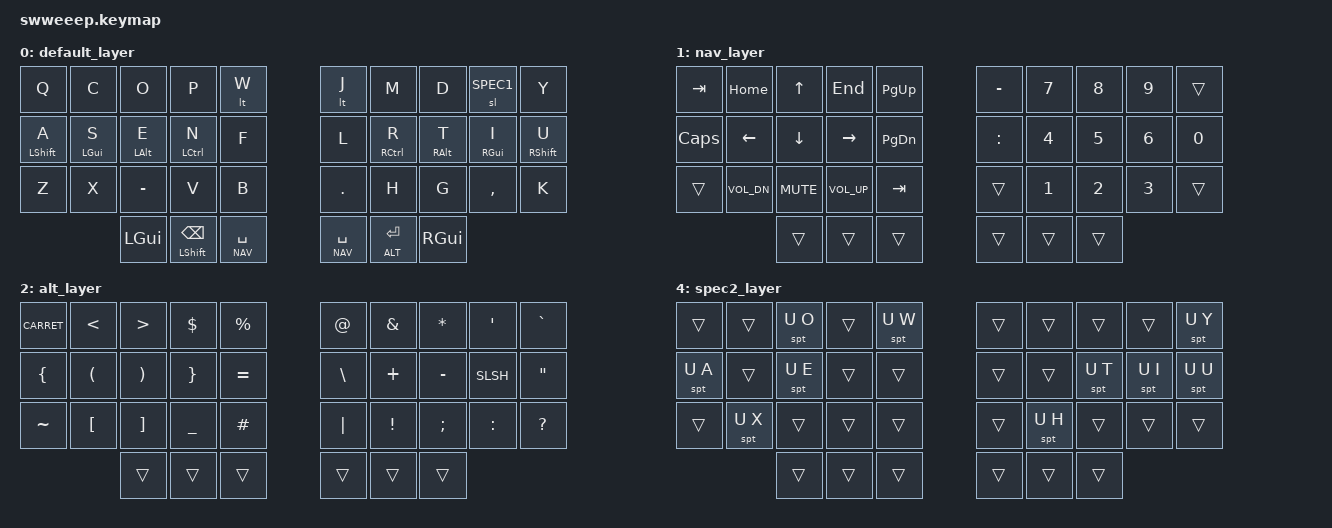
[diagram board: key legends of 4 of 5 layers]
#include <behaviors.dtsi>
#include <dt-bindings/zmk/keys.h>
#include <dt-bindings/zmk/bt.h>
#include <dt-bindings/zmk/ext_power.h>
#include <dt-bindings/zmk/outputs.h>

#define ERGOL   0
#define NAV     1
#define ALT     2
#define SPEC1   3
#define SPEC2   4

&caps_word {
    continue-list = <UNDERSCORE MINUS>;
};

/ {
    combos {
        compatible = "zmk,combos";
        combo_undo {
            timeout-ms = <50>;
            key-positions = <20 21>;
            bindings = <&kp LC(Z)>;
        };
    };
};

/ {
    macros {
	spt: spt {
            compatible = "zmk,behavior-macro";
            #binding-cells = <2>;
            bindings
                = <&macro_press &kp LALT>
                , <&macro_param_1to1>
                , <&macro_release &kp MACRO_PLACEHOLDER>
                , <&macro_release &kp LALT>
		, <&macro_tap &kp LALT>
                , <&macro_param_2to1>
                , <&macro_release &kp MACRO_PLACEHOLDER>
                ;
	};
    };

    behaviors {
        hm: homerow_mods {
            compatible = "zmk,behavior-hold-tap";
            #binding-cells = <2>;
            tapping-term-ms = <200>;
            flavor = "tap-preferred";
            bindings = <&kp>, <&kp>;
        };
        hs: homerow_shift {
            compatible = "zmk,behavior-hold-tap";
            #binding-cells = <2>;
            tapping-term-ms = <175>;
            flavor = "balanced";
            bindings = <&kp>, <&kp>;
        };
    };

    keymap {
        compatible = "zmk,keymap";

        default_layer {
            bindings = <
    &kp Q        &kp C        &kp O       &kp P         &lt W                                       &lt J       &kp M      &kp D      &sl SPEC1  &kp Y
    &hs LSHIFT A &hm LGUI S   &hm LALT E  &hm LCTL N    &kp F                                       &kp L       &hm RCTL R &hm RALT T &hm RGUI I &hs RSHIFT U
    &kp Z        &kp X        &kp -       &kp V         &kp B                                       &kp DOT     &kp H      &kp G      &kp COMMA  &kp K
                                          &kp LGUI      &hs LSHIFT BSPC &lt NAV SPACE &lt NAV SPACE &lt ALT RET &kp RGUI
            >;
        };

        nav_layer {
            bindings = <
    &kp TAB      &kp HOME     &kp UP      &kp END       &kp PG_UP                                   &kp MINUS     &kp N7       &kp N8        &kp N9      &trans
    &kp CAPS     &kp LEFT     &kp DOWN    &kp RIGHT     &kp PG_DN                                   &kp COLON     &kp N4       &kp N5        &kp N6      &kp N0
    &trans       &kp C_VOL_DN &kp C_MUTE  &kp C_VOL_UP  &kp TAB                                     &trans        &kp N1       &kp N2        &kp N3      &trans
                                          &trans        &trans          &trans        &trans        &trans        &trans
            >;
        };

        alt_layer {
            bindings = <
    &kp CARRET   &kp LT       &kp GT      &kp DLLR      &kp PRCNT                                   &kp AT        &kp AMPS     &kp ASTRK     &kp SQT     &kp GRAVE
    &kp LBRC     &kp LPAR     &kp RPAR    &kp RBRC      &kp EQUAL                                   &kp BSLH      &kp PLUS     &kp MINUS     &kp SLSH    &kp DQT
    &kp TILDE    &kp LBKT     &kp RBKT    &kp UNDER     &kp HASH                                    &kp PIPE      &kp EXCL     &kp SEMI      &kp COLON   &kp QMARK
                                          &trans        &trans         &trans        &trans         &trans        &trans
            >;
        };

        spec1_layer {
            bindings = <
    &spt N6 A    &spt C C     &trans       &spt N6 O    &trans                                      &trans        &kp F7       &kp UNDER   &sl SPEC2   &spt N6 U
    &spt GRAVE A &spt E E     &spt GRAVE E &spt N6 E    &spt TILDE N                                &kp LPAR      &kp RPAR     &spt N6     &kp U I     &spt GRAVE U
    &kp  A       &spt E S     &trans       &trans       &trans                                      &trans        &trans       &trans      &trans      &trans
                                           &trans       &trans         &trans        &trans         &trans        &trans
            >;
        };

        spec2_layer {
            bindings = <
    &trans       &trans       &spt U O      &trans      &spt U W                                    &trans        &trans       &trans      &trans      &spt U Y
    &spt U A     &trans       &spt U E      &trans      &trans                                      &trans        &trans       &spt U T    &spt U I    &spt U U
    &trans       &spt U X     &trans        &trans      &trans                                      &trans        &spt U H     &trans      &trans      &trans
                                            &trans      &trans         &trans        &trans         &trans        &trans
            >;
        };
    };
};
